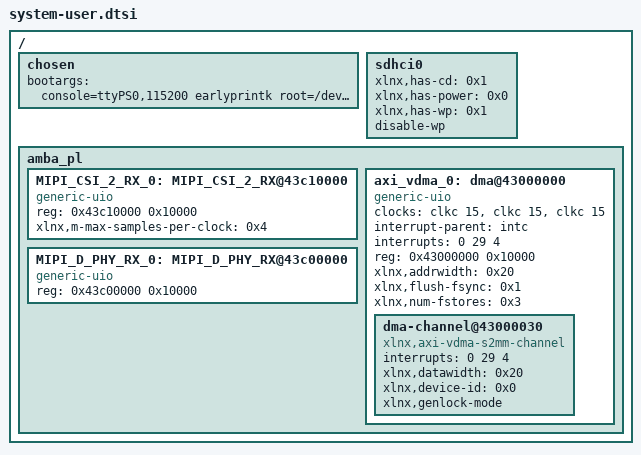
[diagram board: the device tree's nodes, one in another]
/include/ "system-conf.dtsi"
/ {
	chosen {
    		bootargs = "console=ttyPS0,115200 earlyprintk root=/dev/mmcblk0p2 rw rootfstype=ext4 rootwait uio_pdrv_genirq.of_id=generic-uio";
    	};

	sdhci0 {
		status = "okay";
		xlnx,has-cd = <0x1>;
		xlnx,has-power = <0x0>;
		xlnx,has-wp = <0x1>;
		disable-wp;
	};

	amba_pl: amba_pl {
		MIPI_CSI_2_RX_0: MIPI_CSI_2_RX@43c10000 {
			compatible = "generic-uio";
			reg = <0x43c10000 0x10000>;
			xlnx,m-max-samples-per-clock = <0x4>;
		};
		MIPI_D_PHY_RX_0: MIPI_D_PHY_RX@43c00000 {
			compatible = "generic-uio";
			reg = <0x43c00000 0x10000>;
		};
		axi_vdma_0: dma@43000000 {
			#dma-cells = <1>;
			clock-names = "s_axi_lite_aclk", "m_axi_s2mm_aclk", "m_axi_s2mm_aclk";
			clocks = <&clkc 15>, <&clkc 15>, <&clkc 15>;
			compatible = "generic-uio";
			interrupt-parent = <&intc>;
			interrupts = <0 29 4>;
			reg = <0x43000000 0x10000>;
			xlnx,addrwidth = <0x20>;
			xlnx,flush-fsync = <0x1>;
			xlnx,num-fstores = <0x3>;
			dma-channel@43000030 {
				compatible = "xlnx,axi-vdma-s2mm-channel";
				interrupts = <0 29 4>;
				xlnx,datawidth = <0x20>;
				xlnx,device-id = <0x0>;
				xlnx,genlock-mode ;
			};
		};
	};
};
